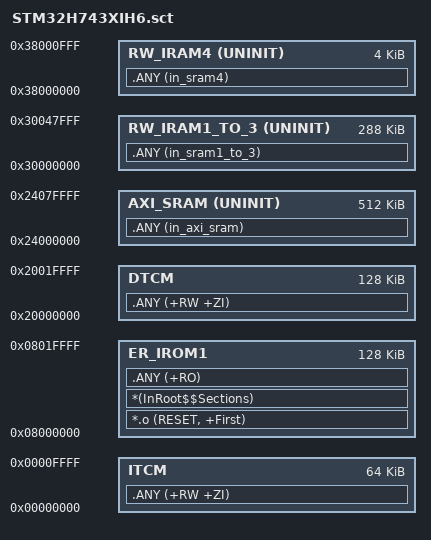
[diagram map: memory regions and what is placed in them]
; *************************************************************
; *** Scatter-Loading Description File generated by uVision ***
; *************************************************************

  LR_IROM1 0x08000000 0x00020000  {    ; load region size_region
  ER_IROM1 0x08000000 0x00020000  {  ; load address = execution address
   *.o (RESET, +First)
   *(InRoot$$Sections)
   .ANY (+RO)
  }
  ITCM 0x0 0x00010000  {  ; RW data
   .ANY (+RW +ZI)
  }   
  DTCM 0x20000000 0x00020000  {  ; RW data
   .ANY (+RW +ZI)
  }
  AXI_SRAM 0x24000000 UNINIT 0x00080000  {
   .ANY (in_axi_sram)
  }
  RW_IRAM1_TO_3 0x30000000 UNINIT 0x00048000  {
   .ANY (in_sram1_to_3)
  }
;  RW_IRAM2 0x30020000 UNINIT 0x00040000  {
;   .ANY (in_sram2)
;  }
;  RW_IRAM3 0x30040000 UNINIT 0x00008000  {
;   .ANY (in_sram3)
;  }
  RW_IRAM4 0x38000000 UNINIT 0x00001000  {
   .ANY (in_sram4)
  }
}

